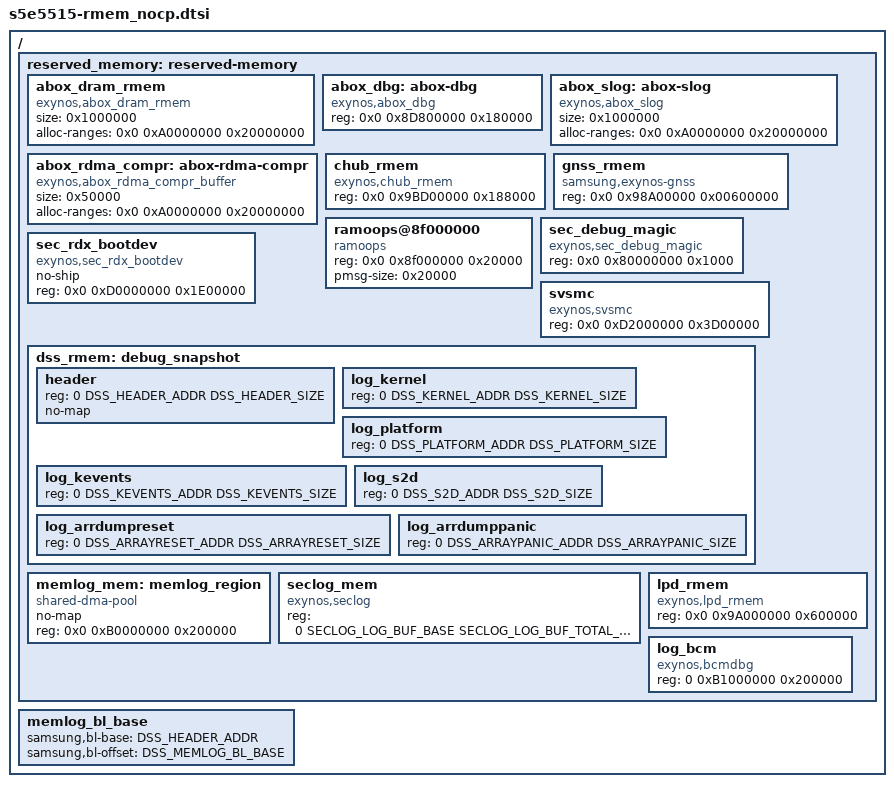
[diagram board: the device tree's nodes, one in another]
/*
 * SAMSUNG EXYNOS device tree source for reserved-memory
 *
 * Copyright (c) 2018 Samsung Electronics Co., Ltd.
 *		http://www.samsung.com
 *
 * This program is free software; you can redistribute it and/or modify
 * it under the terms of the GNU General Public License version 2 as
 * published by the Free Software Foundation.
 */

#include <dt-bindings/soc/samsung/debug-snapshot-def.h>
#include <dt-bindings/soc/samsung/exynos5515-seclog.h>

/ {
	reserved_memory: reserved-memory {
		#address-cells = <2>;
		#size-cells = <1>;
		ranges;

		abox_dram_rmem: abox_dram_rmem {
			compatible = "exynos,abox_dram_rmem";
			size = <0x1000000>;
			alloc-ranges = <0x0 0xA0000000 0x20000000>;
		};

		abox_dbg: abox-dbg {
			compatible = "exynos,abox_dbg";
			reg = <0x0 0x8D800000 0x180000>;
		};

		abox_slog: abox-slog {
			compatible = "exynos,abox_slog";
			size = <0x1000000>;
			alloc-ranges = <0x0 0xA0000000 0x20000000>;
		};

		abox_rdma_compr: abox-rdma-compr {
			compatible = "exynos,abox_rdma_compr_buffer";
			size = <0x50000>;
			alloc-ranges = <0x0 0xA0000000 0x20000000>;
		};

                chub_rmem: chub_rmem {
			compatible = "exynos,chub_rmem";
			/* To dump SHUB SRAM out upon shub firmware crash */
			reg = <0x0 0x9BD00000 0x188000>;
                };

		gnss_rmem: gnss_rmem {
			compatible = "samsung,exynos-gnss";
			reg = <0x0 0x98A00000 0x00600000>;
		};

		ramoops@8f000000 {
			compatible = "ramoops";
			reg = <0x0 0x8f000000 0x20000>;
			pmsg-size = <0x20000>;
		};

		sec_debug_magic {
			compatible = "exynos,sec_debug_magic";
			reg = <0x0 0x80000000 0x1000>;
		};

		sec_rdx_bootdev {
			compatible = "exynos,sec_rdx_bootdev";
			no-ship;
			reg = <0x0 0xD0000000 0x1E00000>;
		};

		svsmc {
			compatible = "exynos,svsmc";
			reg = <0x0 0xD2000000 0x3D00000>;
		};

                dss_rmem: debug_snapshot {
                        #address-cells = <2>;
                        #size-cells = <1>;
                        header: header {
                                reg = <0 DSS_HEADER_ADDR DSS_HEADER_SIZE>;
				no-map;
                        };
                        log_kernel: log_kernel {
                                reg = <0 DSS_KERNEL_ADDR DSS_KERNEL_SIZE>;
                        };
			log_platform: log_platform {
				reg = <0 DSS_PLATFORM_ADDR DSS_PLATFORM_SIZE>;
			};
			log_kevents: log_kevents {
				reg = <0 DSS_KEVENTS_ADDR DSS_KEVENTS_SIZE>;
			};
			log_s2d: log_s2d {
				reg = <0 DSS_S2D_ADDR DSS_S2D_SIZE>;
			};
			log_arrdumpreset: log_arrdumpreset {
				reg = <0 DSS_ARRAYRESET_ADDR DSS_ARRAYRESET_SIZE>;
			};
			log_arrdumppanic: log_arrdumppanic {
				reg = <0 DSS_ARRAYPANIC_ADDR DSS_ARRAYPANIC_SIZE>;
			};

                };

		memlog_mem: memlog_region {
			compatible = "shared-dma-pool";
			no-map;
			reg = <0x0 0xB0000000 0x200000>;
		};

		seclog_mem {
			compatible = "exynos,seclog";
			reg = <0 SECLOG_LOG_BUF_BASE SECLOG_LOG_BUF_TOTAL_SIZE>;
		};

		lpd_rmem: lpd_rmem {
			compatible = "exynos,lpd_rmem";
			reg = <0x0 0x9A000000 0x600000>;
		};

                log_bcm: log_bcm {
                        compatible = "exynos,bcmdbg";
                        reg = <0 0xB1000000 0x200000>;
                };
	};

	memlog_bl_base: memlog_bl_base {
		samsung,bl-base = <DSS_HEADER_ADDR>;
		samsung,bl-offset = <DSS_MEMLOG_BL_BASE>;
	};
};
